# cc13x2_cc26x2 register map
File version: 2.1
CPU: CM4 r0p1, little endian, MPU, FPU, 3 interrupt priority bits
Registers are 32-bit, read-write, reset 0x0 unless marked. A register's access mark holds for its fields unless they carry their own. Offsets are from the block's base; [hi:lo] are bit positions; {n}, {i} and the like mark numbered series.

## FLASH — Flash sub-system registers, includes the Flash Memory Controller (FMC), flash read path, and an integrated Efuse controller and EFUSEROM.
Base 0x40030000
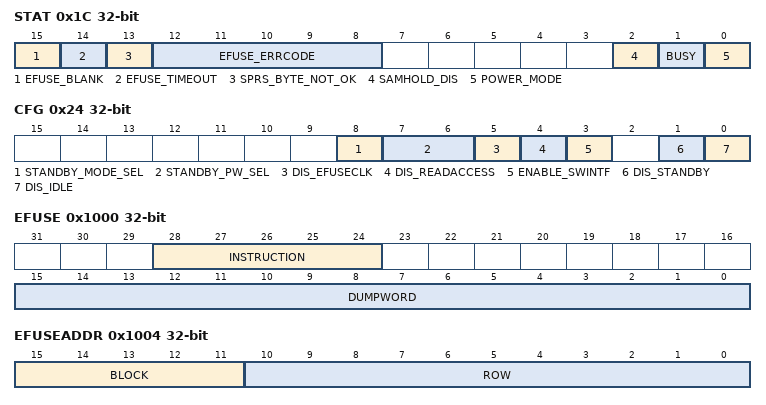
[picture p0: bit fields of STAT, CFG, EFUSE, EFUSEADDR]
0x1C STAT ro — FMC and Efuse Status
  [15] EFUSE_BLANK, [14] EFUSE_TIMEOUT, [13] SPRS_BYTE_NOT_OK, [12:8] EFUSE_ERRCODE, [2] SAMHOLD_DIS, [1] BUSY, [0] POWER_MODE
0x24 CFG — Internal. Only to be used through TI provided API.
  [8] STANDBY_MODE_SEL, [7:6] STANDBY_PW_SEL, [5] DIS_EFUSECLK, [4] DIS_READACCESS, [3] ENABLE_SWINTF, [1] DIS_STANDBY, [0] DIS_IDLE
0x28 SYSCODE_START — Internal. Only to be used through TI provided API.
  [5:0] SYSCODE_START
0x2C FLASH_SIZE — Internal. Only to be used through TI provided API.
  [7:0] SECTORS
0x3C FWLOCK — Internal. Only to be used through TI provided API.
  [2:0] FWLOCK
0x40 FWFLAG — Internal. Only to be used through TI provided API.
  [2:0] FWFLAG
0x1000 EFUSE — Internal. Only to be used through TI provided API.
  [28:24] INSTRUCTION, [15:0] DUMPWORD
0x1004 EFUSEADDR — Internal. Only to be used through TI provided API.
  [15:11] BLOCK, [10:0] ROW
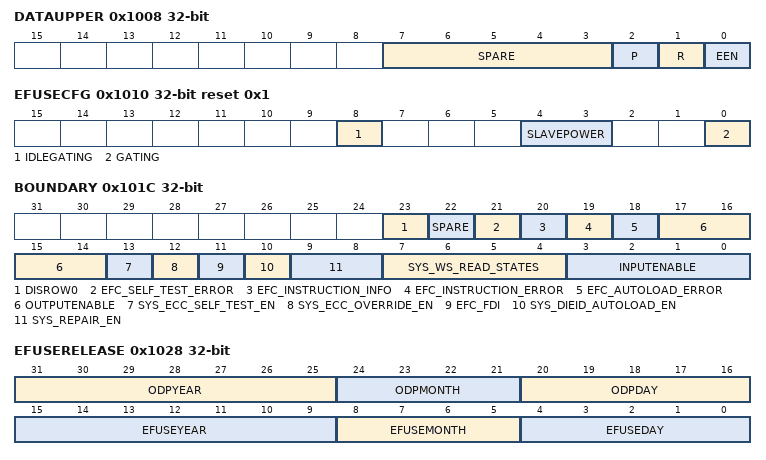
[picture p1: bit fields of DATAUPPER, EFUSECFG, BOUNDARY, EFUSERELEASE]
0x1008 DATAUPPER — Internal. Only to be used through TI provided API.
  [7:3] SPARE, [2] P, [1] R, [0] EEN
0x100C DATALOWER — Internal. Only to be used through TI provided API.
  [31:0] DATA
0x1010 EFUSECFG reset 0x1 — Internal. Only to be used through TI provided API.
  [8] IDLEGATING, [4:3] SLAVEPOWER, [0] GATING
0x1014 EFUSESTAT ro reset 0x1 — Internal. Only to be used through TI provided API.
  [0] RESETDONE
0x1018 ACC ro — Internal. Only to be used through TI provided API.
  [23:0] ACCUMULATOR
0x101C BOUNDARY — Internal. Only to be used through TI provided API.
  [23] DISROW0, [22] SPARE, [21] EFC_SELF_TEST_ERROR, [20] EFC_INSTRUCTION_INFO, [19] EFC_INSTRUCTION_ERROR, [18] EFC_AUTOLOAD_ERROR, [17:14] OUTPUTENABLE, [13] SYS_ECC_SELF_TEST_EN, [12] SYS_ECC_OVERRIDE_EN, [11] EFC_FDI, [10] SYS_DIEID_AUTOLOAD_EN, [9:8] SYS_REPAIR_EN, [7:4] SYS_WS_READ_STATES, [3:0] INPUTENABLE
0x1020 EFUSEFLAG ro — Internal. Only to be used through TI provided API.
  [0] KEY
0x1024 EFUSEKEY — Internal. Only to be used through TI provided API.
  [31:0] CODE
0x1028 EFUSERELEASE ro — Internal. Only to be used through TI provided API.
  [31:25] ODPYEAR, [24:21] ODPMONTH, [20:16] ODPDAY, [15:9] EFUSEYEAR, [8:5] EFUSEMONTH, [4:0] EFUSEDAY
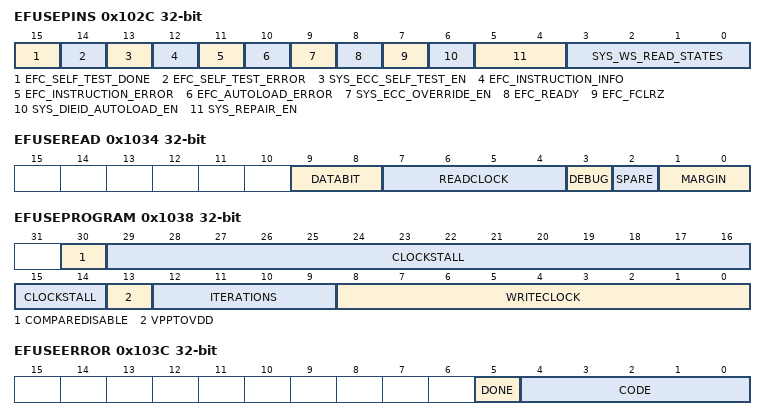
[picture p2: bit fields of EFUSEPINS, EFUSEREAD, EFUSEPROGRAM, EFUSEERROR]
0x102C EFUSEPINS ro — Internal. Only to be used through TI provided API.
  [15] EFC_SELF_TEST_DONE, [14] EFC_SELF_TEST_ERROR, [13] SYS_ECC_SELF_TEST_EN, [12] EFC_INSTRUCTION_INFO, [11] EFC_INSTRUCTION_ERROR, [10] EFC_AUTOLOAD_ERROR, [9] SYS_ECC_OVERRIDE_EN, [8] EFC_READY, [7] EFC_FCLRZ, [6] SYS_DIEID_AUTOLOAD_EN, [5:4] SYS_REPAIR_EN, [3:0] SYS_WS_READ_STATES
0x1030 EFUSECRA — Internal. Only to be used through TI provided API.
  [5:0] DATA
0x1034 EFUSEREAD — Internal. Only to be used through TI provided API.
  [9:8] DATABIT, [7:4] READCLOCK, [3] DEBUG, [2] SPARE, [1:0] MARGIN
0x1038 EFUSEPROGRAM — Internal. Only to be used through TI provided API.
  [30] COMPAREDISABLE, [29:14] CLOCKSTALL, [13] VPPTOVDD, [12:9] ITERATIONS, [8:0] WRITECLOCK
0x103C EFUSEERROR — Internal. Only to be used through TI provided API.
  [5] DONE, [4:0] CODE
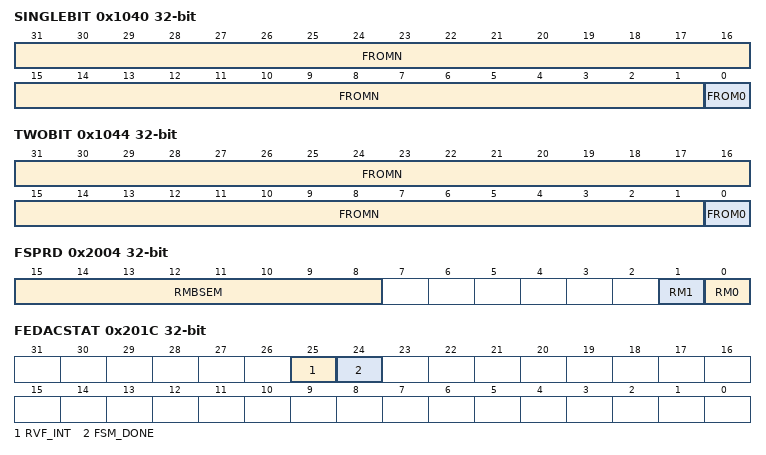
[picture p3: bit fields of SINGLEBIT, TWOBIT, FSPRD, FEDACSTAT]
0x1040 SINGLEBIT ro — Internal. Only to be used through TI provided API.
  [31:1] FROMN, [0] FROM0
0x1044 TWOBIT ro — Internal. Only to be used through TI provided API.
  [31:1] FROMN, [0] FROM0
0x1048 SELFTESTCYC — Internal. Only to be used through TI provided API.
  [31:0] CYCLES
0x104C SELFTESTSIGN — Internal. Only to be used through TI provided API.
  [31:0] SIGNATURE
0x2000 FRDCTL reset 0x200 — Internal. Only to be used through TI provided API.
  [11:8] RWAIT
0x2004 FSPRD — Internal. Only to be used through TI provided API.
  [15:8] RMBSEM, [1] RM1, [0] RM0
0x2008 FEDACCTL1 — Internal. Only to be used through TI provided API.
  [24] SUSP_IGNR
0x201C FEDACSTAT — Internal. Only to be used through TI provided API.
  [25] RVF_INT write-1-clears, [24] FSM_DONE write-1-clears
0x2030 FBPROT — Internal. Only to be used through TI provided API.
  [0] PROTL1DIS
0x2034 FBSE — Internal. Only to be used through TI provided API.
  [15:0] BSE
0x2038 FBBUSY ro reset 0xFE — Internal. Only to be used through TI provided API.
  [7:0] BUSY
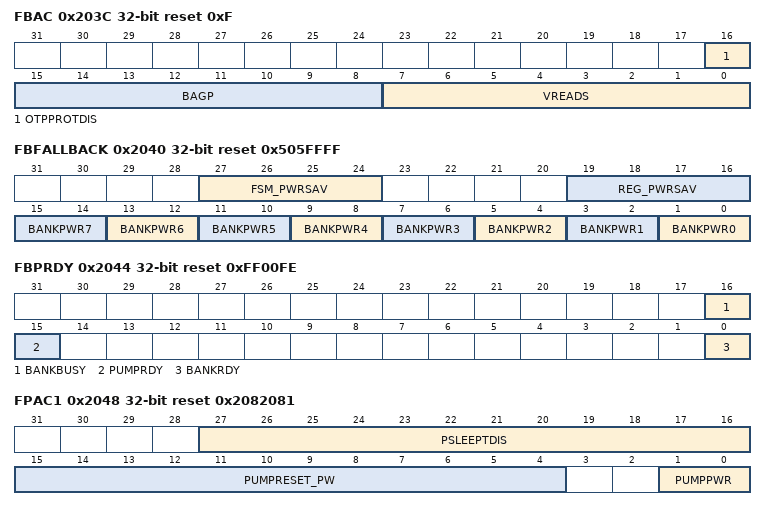
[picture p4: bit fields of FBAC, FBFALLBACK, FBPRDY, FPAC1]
0x203C FBAC reset 0xF — Internal. Only to be used through TI provided API.
  [16] OTPPROTDIS, [15:8] BAGP, [7:0] VREADS
0x2040 FBFALLBACK reset 0x505FFFF — Internal. Only to be used through TI provided API.
  [27:24] FSM_PWRSAV, [19:16] REG_PWRSAV, [2n+1:2n] BANKPWR{n} (n=0..7)
0x2044 FBPRDY ro reset 0xFF00FE — Internal. Only to be used through TI provided API.
  [16] BANKBUSY, [15] PUMPRDY, [0] BANKRDY
0x2048 FPAC1 reset 0x2082081 — Internal. Only to be used through TI provided API.
  [27:16] PSLEEPTDIS, [15:4] PUMPRESET_PW, [1:0] PUMPPWR
0x204C FPAC2 — Internal. Only to be used through TI provided API.
  [15:0] PAGP
0x2050 FMAC — Internal. Only to be used through TI provided API.
  [2:0] BANK
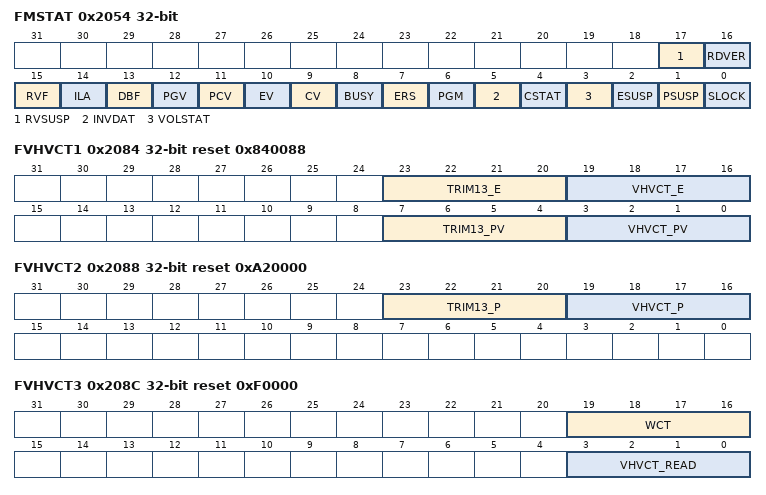
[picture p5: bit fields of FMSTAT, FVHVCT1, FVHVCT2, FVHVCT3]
0x2054 FMSTAT ro — Internal. Only to be used through TI provided API.
  [17] RVSUSP, [16] RDVER, [15] RVF, [14] ILA, [13] DBF, [12] PGV, [11] PCV, [10] EV, [9] CV, [8] BUSY, [7] ERS, [6] PGM, [5] INVDAT, [4] CSTAT, [3] VOLSTAT, [2] ESUSP, [1] PSUSP, [0] SLOCK
0x2064 FLOCK reset 0x55AA — Internal. Only to be used through TI provided API.
  [15:0] ENCOM
0x2080 FVREADCT reset 0x8 — Internal. Only to be used through TI provided API.
  [3:0] VREADCT
0x2084 FVHVCT1 reset 0x840088 — Internal. Only to be used through TI provided API.
  [23:20] TRIM13_E, [19:16] VHVCT_E, [7:4] TRIM13_PV, [3:0] VHVCT_PV
0x2088 FVHVCT2 reset 0xA20000 — Internal. Only to be used through TI provided API.
  [23:20] TRIM13_P, [19:16] VHVCT_P
0x208C FVHVCT3 reset 0xF0000 — Internal. Only to be used through TI provided API.
  [19:16] WCT, [3:0] VHVCT_READ
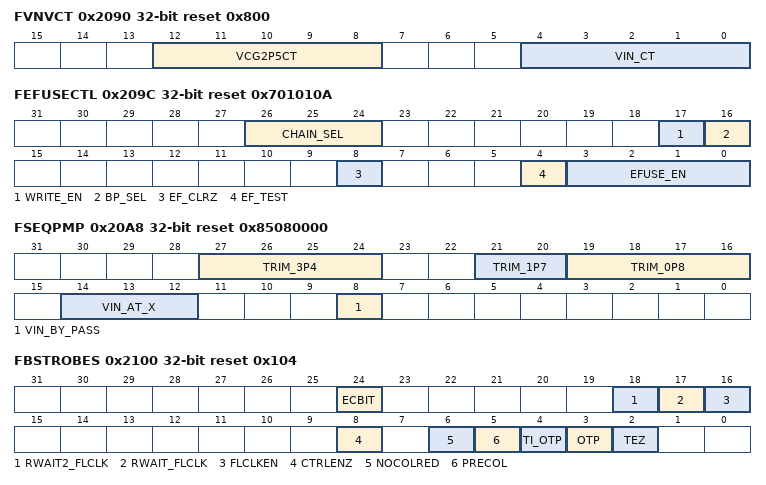
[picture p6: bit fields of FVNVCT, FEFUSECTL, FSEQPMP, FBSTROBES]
0x2090 FVNVCT reset 0x800 — Internal. Only to be used through TI provided API.
  [12:8] VCG2P5CT, [4:0] VIN_CT
0x2094 FVSLP reset 0x8000 — Internal. Only to be used through TI provided API.
  [15:12] VSL_P
0x2098 FVWLCT reset 0x8 — Internal. Only to be used through TI provided API.
  [4:0] VWLCT_P
0x209C FEFUSECTL reset 0x701010A — Internal. Only to be used through TI provided API.
  [26:24] CHAIN_SEL, [17] WRITE_EN, [16] BP_SEL, [8] EF_CLRZ, [4] EF_TEST, [3:0] EFUSE_EN
0x20A0 FEFUSESTAT — Internal. Only to be used through TI provided API.
  [0] SHIFT_DONE write-1-clears
0x20A4 FEFUSEDATA — Internal. Only to be used through TI provided API.
0x20A8 FSEQPMP reset 0x85080000 — Internal. Only to be used through TI provided API.
  [27:24] TRIM_3P4, [21:20] TRIM_1P7, [19:16] TRIM_0P8, [14:12] VIN_AT_X, [8] VIN_BY_PASS
0x2100 FBSTROBES reset 0x104 — Internal. Only to be used through TI provided API.
  [24] ECBIT, [18] RWAIT2_FLCLK, [17] RWAIT_FLCLK, [16] FLCLKEN, [8] CTRLENZ, [6] NOCOLRED, [5] PRECOL, [4] TI_OTP, [3] OTP, [2] TEZ
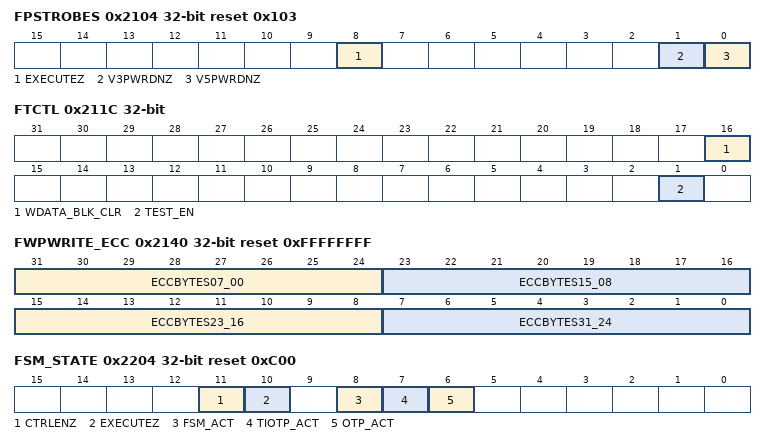
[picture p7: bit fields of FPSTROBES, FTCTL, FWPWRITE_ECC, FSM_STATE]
0x2104 FPSTROBES reset 0x103 — Internal. Only to be used through TI provided API.
  [8] EXECUTEZ, [1] V3PWRDNZ, [0] V5PWRDNZ
0x2108 FBMODE — Internal. Only to be used through TI provided API.
  [2:0] MODE
0x210C FTCR — Internal. Only to be used through TI provided API.
  [6:0] TCR
0x2110 FADDR — Internal. Only to be used through TI provided API.
0x211C FTCTL — Internal. Only to be used through TI provided API.
  [16] WDATA_BLK_CLR, [1] TEST_EN
{0x2120+4i} FWPWRITE{i} reset 0xFFFFFFFF (i=0..7) — Internal. Only to be used through TI provided API.
0x2140 FWPWRITE_ECC reset 0xFFFFFFFF — Internal. Only to be used through TI provided API.
  [31:24] ECCBYTES07_00, [23:16] ECCBYTES15_08, [15:8] ECCBYTES23_16, [7:0] ECCBYTES31_24
0x2144 FSWSTAT ro reset 0x1 — Internal. Only to be used through TI provided API.
  [0] SAFELV
0x2200 FSM_GLBCTL ro reset 0x1 — Internal. Only to be used through TI provided API.
  [0] CLKSEL
0x2204 FSM_STATE ro reset 0xC00 — Internal. Only to be used through TI provided API.
  [11] CTRLENZ, [10] EXECUTEZ, [8] FSM_ACT, [7] TIOTP_ACT, [6] OTP_ACT
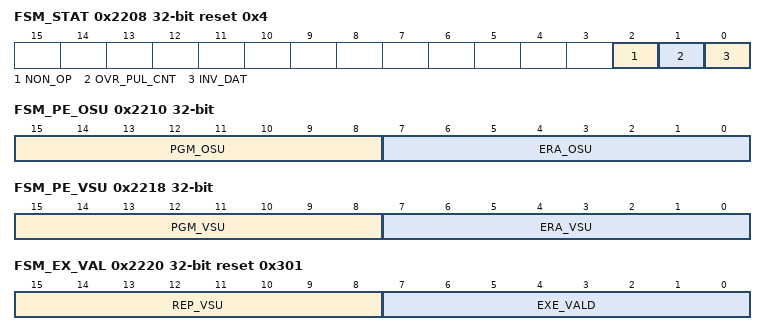
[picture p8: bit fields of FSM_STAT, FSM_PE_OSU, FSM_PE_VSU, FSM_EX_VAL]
0x2208 FSM_STAT ro reset 0x4 — Internal. Only to be used through TI provided API.
  [2] NON_OP, [1] OVR_PUL_CNT, [0] INV_DAT
0x220C FSM_CMD — Internal. Only to be used through TI provided API.
  [5:0] FSMCMD
0x2210 FSM_PE_OSU — Internal. Only to be used through TI provided API.
  [15:8] PGM_OSU, [7:0] ERA_OSU
0x2214 FSM_VSTAT reset 0x3000 — Internal. Only to be used through TI provided API.
  [15:12] VSTAT_CNT
0x2218 FSM_PE_VSU — Internal. Only to be used through TI provided API.
  [15:8] PGM_VSU, [7:0] ERA_VSU
0x221C FSM_CMP_VSU — Internal. Only to be used through TI provided API.
  [15:12] ADD_EXZ
0x2220 FSM_EX_VAL reset 0x301 — Internal. Only to be used through TI provided API.
  [15:8] REP_VSU, [7:0] EXE_VALD
0x2224 FSM_RD_H reset 0x5A — Internal. Only to be used through TI provided API.
  [7:0] RD_H
0x2228 FSM_P_OH reset 0x100 — Internal. Only to be used through TI provided API.
  [15:8] PGM_OH
0x222C FSM_ERA_OH reset 0x1 — Internal. Only to be used through TI provided API.
  [15:0] ERA_OH
0x2230 FSM_SAV_PPUL ro — Internal. Only to be used through TI provided API.
  [11:0] SAV_P_PUL
0x2234 FSM_PE_VH reset 0x100 — Internal. Only to be used through TI provided API.
  [15:8] PGM_VH
0x2240 FSM_PRG_PW — Internal. Only to be used through TI provided API.
  [15:0] PROG_PUL_WIDTH
0x2244 FSM_ERA_PW — Internal. Only to be used through TI provided API.
0x2254 FSM_SAV_ERA_PUL ro — Internal. Only to be used through TI provided API.
  [11:0] SAV_ERA_PUL
0x2258 FSM_TIMER ro — Internal. Only to be used through TI provided API.
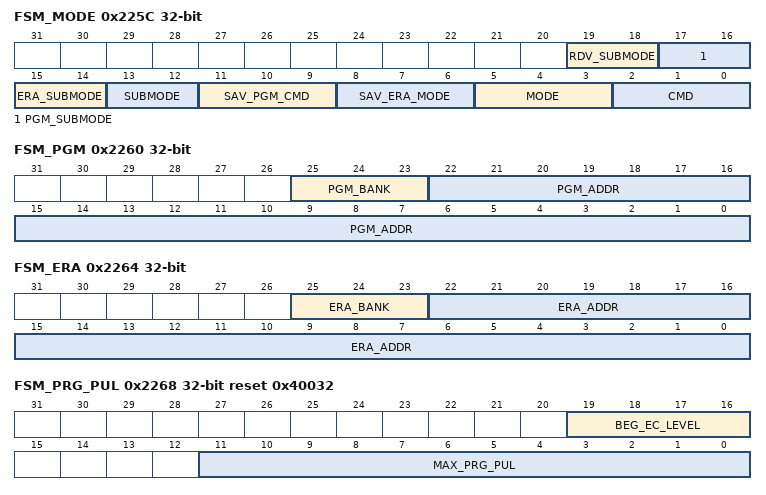
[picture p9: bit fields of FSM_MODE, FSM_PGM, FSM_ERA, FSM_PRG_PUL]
0x225C FSM_MODE ro — Internal. Only to be used through TI provided API.
  [19:18] RDV_SUBMODE, [17:16] PGM_SUBMODE, [15:14] ERA_SUBMODE, [13:12] SUBMODE, [11:9] SAV_PGM_CMD, [8:6] SAV_ERA_MODE, [5:3] MODE, [2:0] CMD
0x2260 FSM_PGM ro — Internal. Only to be used through TI provided API.
  [25:23] PGM_BANK, [22:0] PGM_ADDR
0x2264 FSM_ERA ro — Internal. Only to be used through TI provided API.
  [25:23] ERA_BANK, [22:0] ERA_ADDR
0x2268 FSM_PRG_PUL reset 0x40032 — Internal. Only to be used through TI provided API.
  [19:16] BEG_EC_LEVEL, [11:0] MAX_PRG_PUL
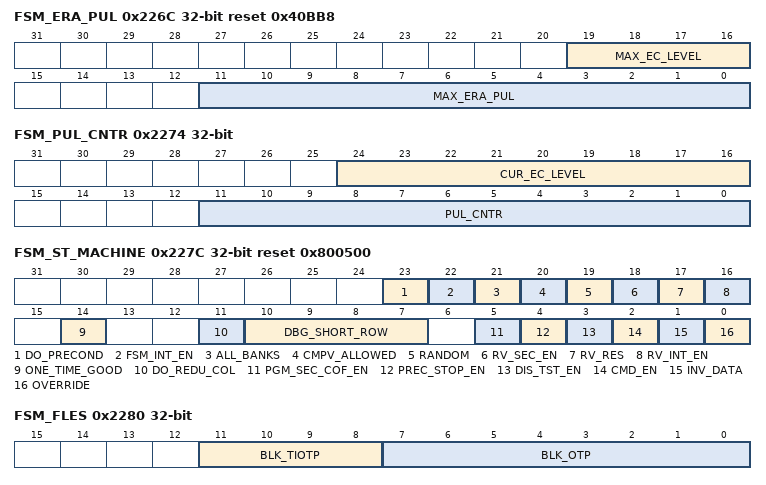
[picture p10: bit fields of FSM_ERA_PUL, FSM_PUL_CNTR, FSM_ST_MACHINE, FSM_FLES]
0x226C FSM_ERA_PUL reset 0x40BB8 — Internal. Only to be used through TI provided API.
  [19:16] MAX_EC_LEVEL, [11:0] MAX_ERA_PUL
0x2270 FSM_STEP_SIZE — Internal. Only to be used through TI provided API.
  [24:16] EC_STEP_SIZE
0x2274 FSM_PUL_CNTR ro — Internal. Only to be used through TI provided API.
  [24:16] CUR_EC_LEVEL, [11:0] PUL_CNTR
0x2278 FSM_EC_STEP_HEIGHT — Internal. Only to be used through TI provided API.
  [3:0] EC_STEP_HEIGHT
0x227C FSM_ST_MACHINE reset 0x800500 — Internal. Only to be used through TI provided API.
  [23] DO_PRECOND, [22] FSM_INT_EN, [21] ALL_BANKS, [20] CMPV_ALLOWED, [19] RANDOM, [18] RV_SEC_EN, [17] RV_RES, [16] RV_INT_EN, [14] ONE_TIME_GOOD, [11] DO_REDU_COL, [10:7] DBG_SHORT_ROW, [5] PGM_SEC_COF_EN, [4] PREC_STOP_EN, [3] DIS_TST_EN, [2] CMD_EN, [1] INV_DATA, [0] OVERRIDE
0x2280 FSM_FLES — Internal. Only to be used through TI provided API.
  [11:8] BLK_TIOTP, [7:0] BLK_OTP
0x2288 FSM_WR_ENA reset 0x2 — Internal. Only to be used through TI provided API.
  [2:0] WR_ENA
0x228C FSM_ACC_PP ro — Internal. Only to be used through TI provided API.
0x2290 FSM_ACC_EP ro — Internal. Only to be used through TI provided API.
  [15:0] ACC_EP
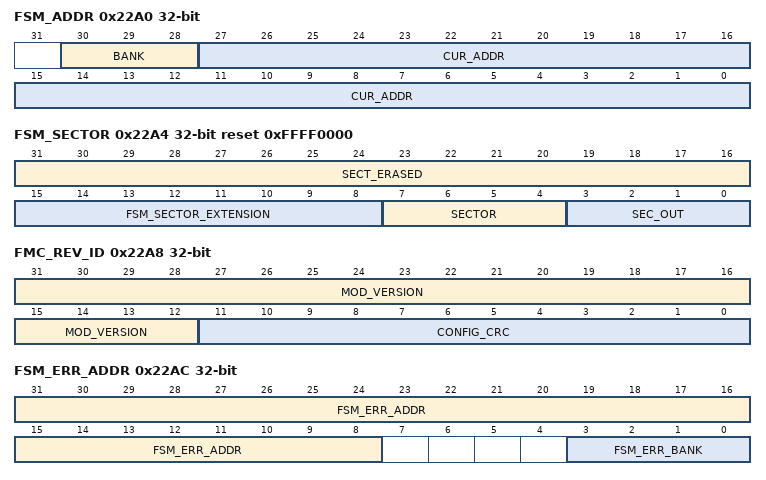
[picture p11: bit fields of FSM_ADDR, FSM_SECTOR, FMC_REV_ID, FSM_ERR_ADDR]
0x22A0 FSM_ADDR ro — Internal. Only to be used through TI provided API.
  [30:28] BANK, [27:0] CUR_ADDR
0x22A4 FSM_SECTOR reset 0xFFFF0000 — Internal. Only to be used through TI provided API.
  [31:16] SECT_ERASED, [15:8] FSM_SECTOR_EXTENSION, [7:4] SECTOR, [3:0] SEC_OUT
0x22A8 FMC_REV_ID ro — Internal. Only to be used through TI provided API.
  [31:12] MOD_VERSION, [11:0] CONFIG_CRC
0x22AC FSM_ERR_ADDR ro — Internal. Only to be used through TI provided API.
  [31:8] FSM_ERR_ADDR, [3:0] FSM_ERR_BANK
0x22B0 FSM_PGM_MAXPUL ro — Internal. Only to be used through TI provided API.
  [11:0] FSM_PGM_MAXPUL
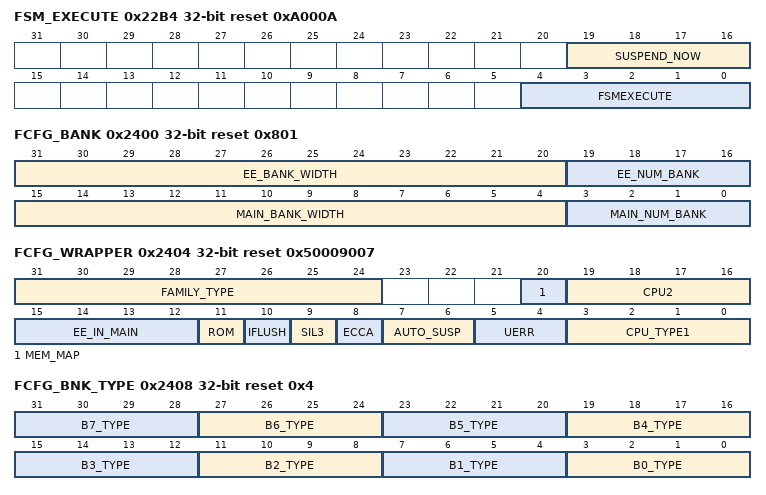
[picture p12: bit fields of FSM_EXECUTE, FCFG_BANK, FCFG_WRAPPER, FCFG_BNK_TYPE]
0x22B4 FSM_EXECUTE reset 0xA000A — Internal. Only to be used through TI provided API.
  [19:16] SUSPEND_NOW, [4:0] FSMEXECUTE
0x22C0 FSM_SECTOR1 reset 0xFFFFFFFF — Internal. Only to be used through TI provided API.
0x22C4 FSM_SECTOR2 reset 0xFFF — Internal. Only to be used through TI provided API.
0x22E0 FSM_BSLE0 — Internal. Only to be used through TI provided API.
0x22E4 FSM_BSLE1 — Internal. Only to be used through TI provided API.
  [31:0] FSM_BSL1
0x22F0 FSM_BSLP0 — Internal. Only to be used through TI provided API.
0x22F4 FSM_BSLP1 — Internal. Only to be used through TI provided API.
  [31:0] FSM_BSL1
0x22F8 FSM_PGM128 — FMC FSM Enable 128-bit Wide Programming
  [0] EN_PGM128
0x2400 FCFG_BANK ro reset 0x801 — Internal. Only to be used through TI provided API.
  [31:20] EE_BANK_WIDTH, [19:16] EE_NUM_BANK, [15:4] MAIN_BANK_WIDTH, [3:0] MAIN_NUM_BANK
0x2404 FCFG_WRAPPER ro reset 0x50009007 — Internal. Only to be used through TI provided API.
  [31:24] FAMILY_TYPE, [20] MEM_MAP, [19:16] CPU2, [15:12] EE_IN_MAIN, [11] ROM, [10] IFLUSH, [9] SIL3, [8] ECCA, [7:6] AUTO_SUSP, [5:4] UERR, [3:0] CPU_TYPE1
0x2408 FCFG_BNK_TYPE ro reset 0x4 — Internal. Only to be used through TI provided API.
  [4n+3:4n] B{n}_TYPE (n=0..7)
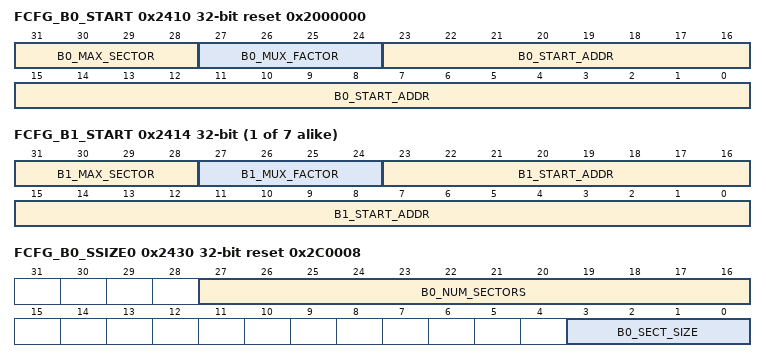
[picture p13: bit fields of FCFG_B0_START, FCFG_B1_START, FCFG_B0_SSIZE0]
0x2410 FCFG_B0_START ro reset 0x2000000 — Internal. Only to be used through TI provided API.
  [31:28] B0_MAX_SECTOR, [27:24] B0_MUX_FACTOR, [23:0] B0_START_ADDR
{0x2410+4i} FCFG_B{i}_START ro (i=1..7) — Internal. Only to be used through TI provided API.
  [31:28] B{i}_MAX_SECTOR, [27:24] B{i}_MUX_FACTOR, [23:0] B{i}_START_ADDR
0x2430 FCFG_B0_SSIZE0 ro reset 0x2C0008 — Internal. Only to be used through TI provided API.
  [27:16] B0_NUM_SECTORS, [3:0] B0_SECT_SIZE
